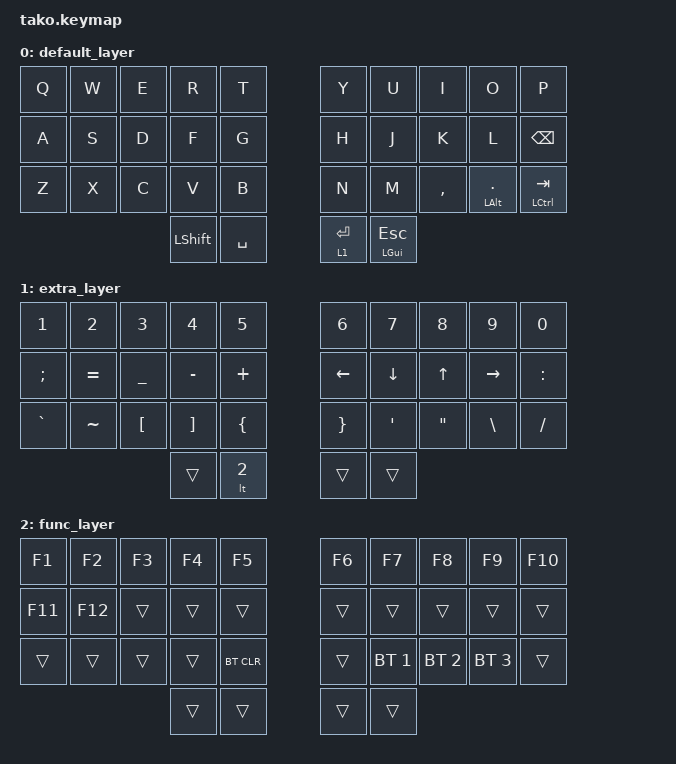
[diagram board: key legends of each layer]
/*
 * Copyright (c) 2020 The ZMK Contributors
 *
 * SPDX-License-Identifier: MIT
 */

#include <behaviors.dtsi>
#include <dt-bindings/zmk/keys.h>
#include <dt-bindings/zmk/bt.h>

&lt {
      flavor="hold-preferred";
};

/ {
    keymap {
        compatible = "zmk,keymap";

        default_layer {
            bindings = <
                &kp Q         &kp W         &kp E         &kp R          &kp T            &kp Y         &kp U         &kp I         &kp O         &kp P
                &kp A         &kp S         &kp D         &kp F          &kp G            &kp H         &kp J         &kp K         &kp L         &kp BSPC
                &kp Z         &kp X         &kp C         &kp V          &kp B            &kp N         &kp M         &kp COMMA     &mt LALT DOT  &mt LCTRL TAB
                                                          &kp LSHFT      &kp SPACE        &lt 1 ENTER   &mt LGUI ESC
            >;
        };

        extra_layer {
            bindings = <
                &kp N1        &kp N2        &kp N3        &kp N4        &kp N5        &kp N6        &kp N7        &kp N8        &kp N9        &kp N0
                &kp SEMI      &kp EQUAL     &kp UNDER     &kp MINUS     &kp PLUS      &kp LEFT      &kp DOWN      &kp UP        &kp RIGHT     &kp COLON
                &kp GRAVE     &kp TILDE     &kp LBKT      &kp RBKT      &kp LBRC      &kp RBRC      &kp SQT       &kp DQT       &kp BSLH      &kp SLASH
                                                          &trans        &lt 2         &trans        &trans
            >;
        };

        func_layer {
            bindings = <
                &kp F1        &kp F2        &kp F3        &kp F4        &kp F5        &kp F6        &kp F7        &kp F8        &kp F9        &kp F10
                &kp F11       &kp F12       &trans        &trans        &trans        &trans        &trans        &trans        &trans        &trans
                &trans        &trans        &trans        &trans        &bt BT_CLR    &trans        &bt BT_SEL 1  &bt BT_SEL 2  &bt BT_SEL 3  &trans
                                                          &trans        &trans        &trans        &trans
            >;
        };

    };
};
